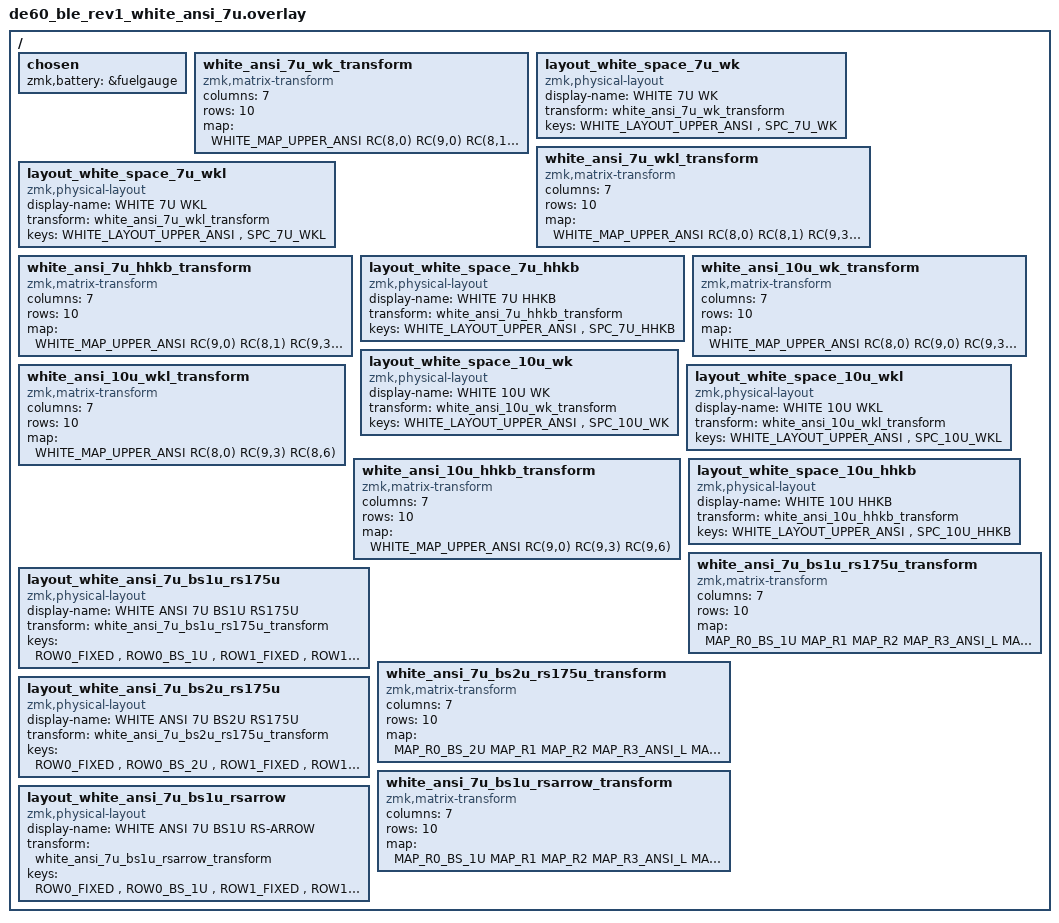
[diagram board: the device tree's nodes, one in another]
#include <dt-bindings/zmk/matrix_transform.h>
#include <physical_layouts.dtsi>
#include "common.overlay"

#define WHITE_MAP_UPPER_ANSI MAP_R0_BS_1U MAP_R1 MAP_R2 MAP_R3_ANSI_L MAP_R3_R
#define WHITE_LAYOUT_UPPER_ANSI ROW0_FIXED , ROW0_BS_1U , ROW1_FIXED , ROW1_ANSI , ROW2_FIXED , ROW2_ANSI , ROW3_ANSI , ROW3_FIXED , ROW3_RS_ARROW

/ {

    chosen {
        zmk,battery = &fuelgauge;
        // zmk,battery = &vbatt;
    };

    // White ANSI 7U Layout
    white_ansi_7u_wk_transform: white_ansi_7u_wk_transform {
        compatible = "zmk,matrix-transform";
        columns = <7>;
        rows = <10>;
        map = <
            WHITE_MAP_UPPER_ANSI
            RC(8,0) RC(9,0) RC(8,1)                         RC(9,3)                                 RC(8,5) RC(9,6) RC(8,6) 
        >;
    };

    layout_white_space_7u_wk: layout_white_space_7u_wk {
        compatible = "zmk,physical-layout";
        display-name = "WHITE 7U WK";
        transform = <&white_ansi_7u_wk_transform>;

        keys =  WHITE_LAYOUT_UPPER_ANSI
                , SPC_7U_WK;
    };

    white_ansi_7u_wkl_transform: white_ansi_7u_wkl_transform {
        compatible = "zmk,matrix-transform";
        columns = <7>;
        rows = <10>;
        map = <
            WHITE_MAP_UPPER_ANSI
            RC(8,0)         RC(8,1)                         RC(9,3)                                 RC(8,5)         RC(8,6) 
        >;
    };

    layout_white_space_7u_wkl: layout_white_space_7u_wkl {
        compatible = "zmk,physical-layout";
        display-name = "WHITE 7U WKL";
        transform = <&white_ansi_7u_wkl_transform>;

        keys =  WHITE_LAYOUT_UPPER_ANSI
                , SPC_7U_WKL;
    };

    white_ansi_7u_hhkb_transform: white_ansi_7u_hhkb_transform {
        compatible = "zmk,matrix-transform";
        columns = <7>;
        rows = <10>;
        map = <
            WHITE_MAP_UPPER_ANSI
                    RC(9,0) RC(8,1)                         RC(9,3)                                 RC(8,5) RC(9,6) 
        >;
    };

    layout_white_space_7u_hhkb: layout_white_space_7u_hhkb {
        compatible = "zmk,physical-layout";
        display-name = "WHITE 7U HHKB";
        transform = <&white_ansi_7u_hhkb_transform>;

        keys =  WHITE_LAYOUT_UPPER_ANSI
                , SPC_7U_HHKB;
    };

    // White ANSI 10U Layout
    white_ansi_10u_wk_transform: white_ansi_10u_wk_transform {
        compatible = "zmk,matrix-transform";
        columns = <7>;
        rows = <10>;
        map = <
            WHITE_MAP_UPPER_ANSI
            RC(8,0) RC(9,0)                                  RC(9,3)                                        RC(9,6) RC(8,6) 
        >;
    };

    layout_white_space_10u_wk: layout_white_space_10u_wk {
        compatible = "zmk,physical-layout";
        display-name = "WHITE 10U WK";
        transform = <&white_ansi_10u_wk_transform>;

        keys =  WHITE_LAYOUT_UPPER_ANSI
                , SPC_10U_WK;
    };

    white_ansi_10u_wkl_transform: white_ansi_10u_wkl_transform {
        compatible = "zmk,matrix-transform";
        columns = <7>;
        rows = <10>;
        map = <
            WHITE_MAP_UPPER_ANSI
            RC(8,0)                                          RC(9,3)                                                RC(8,6) 
        >;
    };

    layout_white_space_10u_wkl: layout_white_space_10u_wkl {
        compatible = "zmk,physical-layout";
        display-name = "WHITE 10U WKL";
        transform = <&white_ansi_10u_wkl_transform>;

        keys =  WHITE_LAYOUT_UPPER_ANSI
                , SPC_10U_WKL;
    };

    white_ansi_10u_hhkb_transform: white_ansi_10u_hhkb_transform {
        compatible = "zmk,matrix-transform";
        columns = <7>;
        rows = <10>;
        map = <
            WHITE_MAP_UPPER_ANSI
                    RC(9,0)                                  RC(9,3)                                        RC(9,6) 
        >;
    };

    layout_white_space_10u_hhkb: layout_white_space_10u_hhkb {
        compatible = "zmk,physical-layout";
        display-name = "WHITE 10U HHKB";
        transform = <&white_ansi_10u_hhkb_transform>;

        keys =  WHITE_LAYOUT_UPPER_ANSI
                , SPC_10U_HHKB;
    };

    /* Additional ANSI 7U variants requested by user */

    /* ANSI 7U - BS 1U, RS 175U */
    white_ansi_7u_bs1u_rs175u_transform: white_ansi_7u_bs1u_rs175u_transform {
        compatible = "zmk,matrix-transform";
        columns = <7>;
        rows = <10>;
        map = <
            MAP_R0_BS_1U MAP_R1 MAP_R2 MAP_R3_ANSI_L MAP_R3_R WHT_MAP_R4_7U_WK
        >;
    };

    layout_white_ansi_7u_bs1u_rs175u: layout_white_ansi_7u_bs1u_rs175u {
        compatible = "zmk,physical-layout";
        display-name = "WHITE ANSI 7U BS1U RS175U";
        transform = <&white_ansi_7u_bs1u_rs175u_transform>;

        keys = ROW0_FIXED , ROW0_BS_1U , ROW1_FIXED , ROW1_ANSI , ROW2_FIXED , ROW2_ANSI , ROW3_ANSI , ROW3_FIXED , ROW3_RS_175U , ROW4_7U_WK;
    };

    /* ANSI 7U - BS 2U, RS 175U */
    white_ansi_7u_bs2u_rs175u_transform: white_ansi_7u_bs2u_rs175u_transform {
        compatible = "zmk,matrix-transform";
        columns = <7>;
        rows = <10>;
        map = <
            MAP_R0_BS_2U MAP_R1 MAP_R2 MAP_R3_ANSI_L MAP_R3_R WHT_MAP_R4_7U_WK
        >;
    };

    layout_white_ansi_7u_bs2u_rs175u: layout_white_ansi_7u_bs2u_rs175u {
        compatible = "zmk,physical-layout";
        display-name = "WHITE ANSI 7U BS2U RS175U";
        transform = <&white_ansi_7u_bs2u_rs175u_transform>;

        keys = ROW0_FIXED , ROW0_BS_2U , ROW1_FIXED , ROW1_ANSI , ROW2_FIXED , ROW2_ANSI , ROW3_ANSI , ROW3_FIXED , ROW3_RS_175U , ROW4_7U_WK;
    };

    /* ANSI 7U - BS 1U, RS Arrow */
    white_ansi_7u_bs1u_rsarrow_transform: white_ansi_7u_bs1u_rsarrow_transform {
        compatible = "zmk,matrix-transform";
        columns = <7>;
        rows = <10>;
        map = <
            MAP_R0_BS_1U MAP_R1 MAP_R2 MAP_R3_ANSI_L MAP_R3_R WHT_MAP_R4_7U_ARROW
        >;
    };

    layout_white_ansi_7u_bs1u_rsarrow: layout_white_ansi_7u_bs1u_rsarrow {
        compatible = "zmk,physical-layout";
        display-name = "WHITE ANSI 7U BS1U RS-ARROW";
        transform = <&white_ansi_7u_bs1u_rsarrow_transform>;

        keys = ROW0_FIXED , ROW0_BS_1U , ROW1_FIXED , ROW1_ANSI , ROW2_FIXED , ROW2_ANSI , ROW3_ANSI , ROW3_FIXED , ROW3_RS_ARROW , ROW4_7U_ARROW;
    };

};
